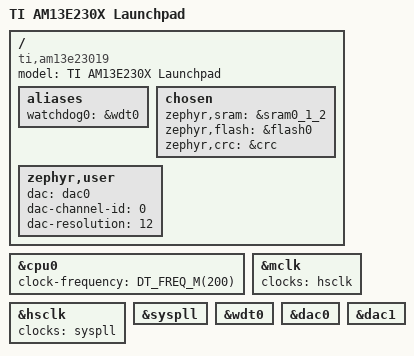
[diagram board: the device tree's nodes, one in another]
/*
 * Copyright (c) 2026 Texas Instruments Incorporated
 *
 * SPDX-License-Identifier: Apache-2.0
 */

/dts-v1/;

#include <ti/am13/am13e23019.dtsi>
#include <ti/am13/am13e23019-pinctrl.dtsi>

/ {
	compatible = "ti,am13e23019";
	model = "TI AM13E230X Launchpad";

	aliases {
		watchdog0 = &wdt0;
	};

	chosen {
		zephyr,sram = &sram0_1_2;
		zephyr,flash = &flash0;
		zephyr,crc = &crc;
	};

	zephyr,user {
		dac = <&dac0>;
		dac-channel-id = <0>;
		dac-resolution = <12>;
	};
};

&cpu0 {
	clock-frequency = <DT_FREQ_M(200)>;
};

&mclk {
	clocks = <&hsclk>;
};

&hsclk {
	clocks = <&syspll>;
	status = "okay";
};

&syspll {
	status = "okay";
};

&wdt0 {
	status = "okay";
};

&dac0 {
	status = "okay";
};

&dac1 {
	status = "okay";
};
